# MCU_FSS0_HYPERBUS1P0_0_HPB_ECC_AGGR register map
Vendor: Texas Instruments
Peripheral module from a debugger description file (folder J721S2).
Registers are 32-bit, access not given, reset 0x0 unless marked. A register's access mark holds for its fields unless they carry their own. Offsets are as the file gives them; lines under a group give offsets from that group; [hi:lo] are bit positions; {n}, {i} and the like mark numbered series; 'fields as' and 'values as' point back to an identical list; <NAME> marks a mode.

## MCU_FSS0_HYPERBUS1P0_0_HPB_ECC_AGGR
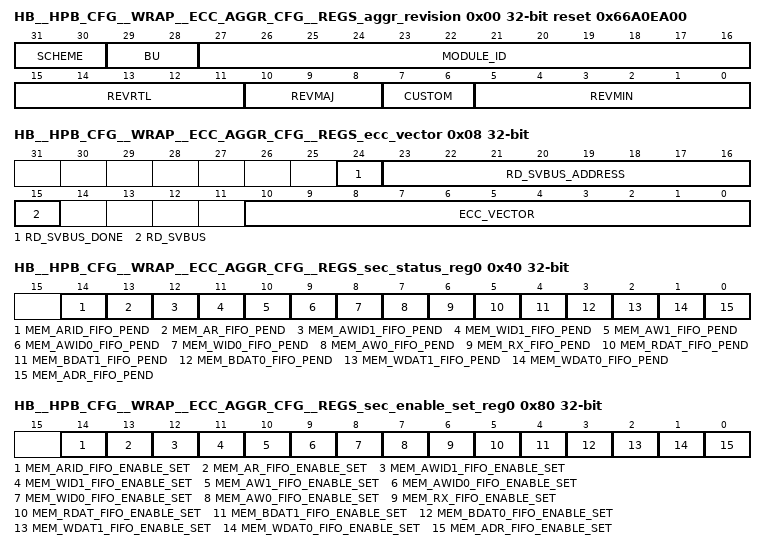
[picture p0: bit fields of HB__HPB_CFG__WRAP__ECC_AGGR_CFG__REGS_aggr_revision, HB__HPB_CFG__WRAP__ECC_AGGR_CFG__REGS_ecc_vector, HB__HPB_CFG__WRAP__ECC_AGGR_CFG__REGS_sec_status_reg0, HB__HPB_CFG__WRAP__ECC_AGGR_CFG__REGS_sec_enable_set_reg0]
0x00 HB__HPB_CFG__WRAP__ECC_AGGR_CFG__REGS_aggr_revision ro reset 0x66A0EA00 — Revision parameters
  [31:30] SCHEME
  [29:28] BU
  [27:16] MODULE_ID
  [15:11] REVRTL — RTL version
  [10:8] REVMAJ — Major version
  [7:6] CUSTOM — Custom version
  [5:0] REVMIN — Minor version
0x08 HB__HPB_CFG__WRAP__ECC_AGGR_CFG__REGS_ecc_vector — ECC Vector Register
  [24] RD_SVBUS_DONE — Status to indicate if read on serial VBUS is complete, write of any value will clear this bit. (access R/W1TC)
  [23:16] RD_SVBUS_ADDRESS rw — Read address
  [15] RD_SVBUS — Write 1 to trigger a read on the serial VBUS (access R/W1TS)
  [10:0] ECC_VECTOR rw — Value written to select the corresponding ECC RAM for control or status
0x0C HB__HPB_CFG__WRAP__ECC_AGGR_CFG__REGS_misc_status ro reset 0xF — Misc Status
  [10:0] NUM_RAMS — Indicates the number of RAMS serviced by the ECC aggregator
0x10 HB__HPB_CFG__WRAP__ECC_AGGR_CFG__REGS_reserved_svbus rw — Reference other documents that contain the ECC RAM wrapper and EDC controller serial vbus register sets.
  [31:0] DATA — Serial VBUS register data
0x3C HB__HPB_CFG__WRAP__ECC_AGGR_CFG__REGS_sec_eoi_reg — EOI Register
  [0] EOI_WR — EOI Register (access R/W1TS)
0x40 HB__HPB_CFG__WRAP__ECC_AGGR_CFG__REGS_sec_status_reg0 — Interrupt Status Register 0
  [14] MEM_ARID_FIFO_PEND — Interrupt Pending Status for mem_arid_fifo_pend (access R/W1TS)
  [13] MEM_AR_FIFO_PEND — Interrupt Pending Status for mem_ar_fifo_pend (access R/W1TS)
  [12] MEM_AWID1_FIFO_PEND — Interrupt Pending Status for mem_awid1_fifo_pend (access R/W1TS)
  [11] MEM_WID1_FIFO_PEND — Interrupt Pending Status for mem_wid1_fifo_pend (access R/W1TS)
  [10] MEM_AW1_FIFO_PEND — Interrupt Pending Status for mem_aw1_fifo_pend (access R/W1TS)
  [9] MEM_AWID0_FIFO_PEND — Interrupt Pending Status for mem_awid0_fifo_pend (access R/W1TS)
  [8] MEM_WID0_FIFO_PEND — Interrupt Pending Status for mem_wid0_fifo_pend (access R/W1TS)
  [7] MEM_AW0_FIFO_PEND — Interrupt Pending Status for mem_aw0_fifo_pend (access R/W1TS)
  [6] MEM_RX_FIFO_PEND — Interrupt Pending Status for mem_rx_fifo_pend (access R/W1TS)
  [5] MEM_RDAT_FIFO_PEND — Interrupt Pending Status for mem_rdat_fifo_pend (access R/W1TS)
  [4] MEM_BDAT1_FIFO_PEND — Interrupt Pending Status for mem_bdat1_fifo_pend (access R/W1TS)
  [3] MEM_BDAT0_FIFO_PEND — Interrupt Pending Status for mem_bdat0_fifo_pend (access R/W1TS)
  [2] MEM_WDAT1_FIFO_PEND — Interrupt Pending Status for mem_wdat1_fifo_pend (access R/W1TS)
  [1] MEM_WDAT0_FIFO_PEND — Interrupt Pending Status for mem_wdat0_fifo_pend (access R/W1TS)
  [0] MEM_ADR_FIFO_PEND — Interrupt Pending Status for mem_adr_fifo_pend (access R/W1TS)
0x80 HB__HPB_CFG__WRAP__ECC_AGGR_CFG__REGS_sec_enable_set_reg0 — Interrupt Enable Set Register 0
  [14] MEM_ARID_FIFO_ENABLE_SET — Interrupt Enable Set Register for mem_arid_fifo_pend (access R/W1TS)
  [13] MEM_AR_FIFO_ENABLE_SET — Interrupt Enable Set Register for mem_ar_fifo_pend (access R/W1TS)
  [12] MEM_AWID1_FIFO_ENABLE_SET — Interrupt Enable Set Register for mem_awid1_fifo_pend (access R/W1TS)
  [11] MEM_WID1_FIFO_ENABLE_SET — Interrupt Enable Set Register for mem_wid1_fifo_pend (access R/W1TS)
  [10] MEM_AW1_FIFO_ENABLE_SET — Interrupt Enable Set Register for mem_aw1_fifo_pend (access R/W1TS)
  [9] MEM_AWID0_FIFO_ENABLE_SET — Interrupt Enable Set Register for mem_awid0_fifo_pend (access R/W1TS)
  [8] MEM_WID0_FIFO_ENABLE_SET — Interrupt Enable Set Register for mem_wid0_fifo_pend (access R/W1TS)
  [7] MEM_AW0_FIFO_ENABLE_SET — Interrupt Enable Set Register for mem_aw0_fifo_pend (access R/W1TS)
  [6] MEM_RX_FIFO_ENABLE_SET — Interrupt Enable Set Register for mem_rx_fifo_pend (access R/W1TS)
  [5] MEM_RDAT_FIFO_ENABLE_SET — Interrupt Enable Set Register for mem_rdat_fifo_pend (access R/W1TS)
  [4] MEM_BDAT1_FIFO_ENABLE_SET — Interrupt Enable Set Register for mem_bdat1_fifo_pend (access R/W1TS)
  [3] MEM_BDAT0_FIFO_ENABLE_SET — Interrupt Enable Set Register for mem_bdat0_fifo_pend (access R/W1TS)
  [2] MEM_WDAT1_FIFO_ENABLE_SET — Interrupt Enable Set Register for mem_wdat1_fifo_pend (access R/W1TS)
  [1] MEM_WDAT0_FIFO_ENABLE_SET — Interrupt Enable Set Register for mem_wdat0_fifo_pend (access R/W1TS)
  [0] MEM_ADR_FIFO_ENABLE_SET — Interrupt Enable Set Register for mem_adr_fifo_pend (access R/W1TS)
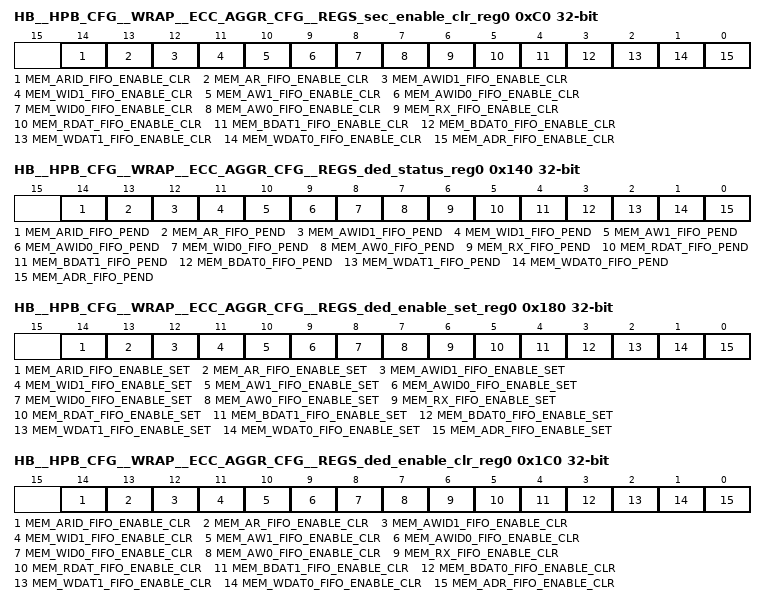
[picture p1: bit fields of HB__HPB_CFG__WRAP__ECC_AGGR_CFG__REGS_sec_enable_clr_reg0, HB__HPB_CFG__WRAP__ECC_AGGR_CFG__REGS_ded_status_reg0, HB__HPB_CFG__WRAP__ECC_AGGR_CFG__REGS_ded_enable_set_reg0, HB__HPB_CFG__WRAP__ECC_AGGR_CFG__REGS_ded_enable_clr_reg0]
0xC0 HB__HPB_CFG__WRAP__ECC_AGGR_CFG__REGS_sec_enable_clr_reg0 — Interrupt Enable Clear Register 0
  [14] MEM_ARID_FIFO_ENABLE_CLR — Interrupt Enable Clear Register for mem_arid_fifo_pend (access R/W1TC)
  [13] MEM_AR_FIFO_ENABLE_CLR — Interrupt Enable Clear Register for mem_ar_fifo_pend (access R/W1TC)
  [12] MEM_AWID1_FIFO_ENABLE_CLR — Interrupt Enable Clear Register for mem_awid1_fifo_pend (access R/W1TC)
  [11] MEM_WID1_FIFO_ENABLE_CLR — Interrupt Enable Clear Register for mem_wid1_fifo_pend (access R/W1TC)
  [10] MEM_AW1_FIFO_ENABLE_CLR — Interrupt Enable Clear Register for mem_aw1_fifo_pend (access R/W1TC)
  [9] MEM_AWID0_FIFO_ENABLE_CLR — Interrupt Enable Clear Register for mem_awid0_fifo_pend (access R/W1TC)
  [8] MEM_WID0_FIFO_ENABLE_CLR — Interrupt Enable Clear Register for mem_wid0_fifo_pend (access R/W1TC)
  [7] MEM_AW0_FIFO_ENABLE_CLR — Interrupt Enable Clear Register for mem_aw0_fifo_pend (access R/W1TC)
  [6] MEM_RX_FIFO_ENABLE_CLR — Interrupt Enable Clear Register for mem_rx_fifo_pend (access R/W1TC)
  [5] MEM_RDAT_FIFO_ENABLE_CLR — Interrupt Enable Clear Register for mem_rdat_fifo_pend (access R/W1TC)
  [4] MEM_BDAT1_FIFO_ENABLE_CLR — Interrupt Enable Clear Register for mem_bdat1_fifo_pend (access R/W1TC)
  [3] MEM_BDAT0_FIFO_ENABLE_CLR — Interrupt Enable Clear Register for mem_bdat0_fifo_pend (access R/W1TC)
  [2] MEM_WDAT1_FIFO_ENABLE_CLR — Interrupt Enable Clear Register for mem_wdat1_fifo_pend (access R/W1TC)
  [1] MEM_WDAT0_FIFO_ENABLE_CLR — Interrupt Enable Clear Register for mem_wdat0_fifo_pend (access R/W1TC)
  [0] MEM_ADR_FIFO_ENABLE_CLR — Interrupt Enable Clear Register for mem_adr_fifo_pend (access R/W1TC)
0x13C HB__HPB_CFG__WRAP__ECC_AGGR_CFG__REGS_ded_eoi_reg — EOI Register
  [0] EOI_WR — EOI Register (access R/W1TS)
0x140 HB__HPB_CFG__WRAP__ECC_AGGR_CFG__REGS_ded_status_reg0 — Interrupt Status Register 0
  fields as HB__HPB_CFG__WRAP__ECC_AGGR_CFG__REGS_sec_status_reg0
0x180 HB__HPB_CFG__WRAP__ECC_AGGR_CFG__REGS_ded_enable_set_reg0 — Interrupt Enable Set Register 0
  fields as HB__HPB_CFG__WRAP__ECC_AGGR_CFG__REGS_sec_enable_set_reg0
0x1C0 HB__HPB_CFG__WRAP__ECC_AGGR_CFG__REGS_ded_enable_clr_reg0 — Interrupt Enable Clear Register 0
  fields as HB__HPB_CFG__WRAP__ECC_AGGR_CFG__REGS_sec_enable_clr_reg0
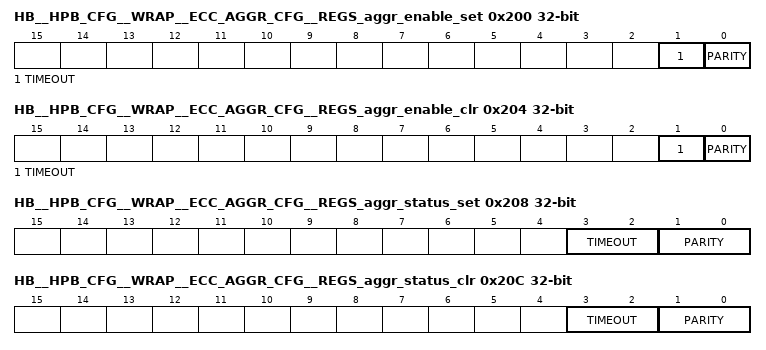
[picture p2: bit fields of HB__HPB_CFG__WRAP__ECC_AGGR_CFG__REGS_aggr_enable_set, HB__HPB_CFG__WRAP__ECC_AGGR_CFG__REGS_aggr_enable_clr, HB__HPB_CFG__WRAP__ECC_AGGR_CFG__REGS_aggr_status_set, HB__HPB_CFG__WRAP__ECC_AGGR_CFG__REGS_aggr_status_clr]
0x200 HB__HPB_CFG__WRAP__ECC_AGGR_CFG__REGS_aggr_enable_set — AGGR interrupt enable set Register
  [1] TIMEOUT — interrupt enable set for svbus timeout errors (access R/W1TS)
  [0] PARITY — interrupt enable set for parity errors (access R/W1TS)
0x204 HB__HPB_CFG__WRAP__ECC_AGGR_CFG__REGS_aggr_enable_clr — AGGR interrupt enable clear Register
  [1] TIMEOUT — interrupt enable clear for svbus timeout errors (access R/W1TC)
  [0] PARITY — interrupt enable clear for parity errors (access R/W1TC)
0x208 HB__HPB_CFG__WRAP__ECC_AGGR_CFG__REGS_aggr_status_set — AGGR interrupt status set Register
  [3:2] TIMEOUT — interrupt status set for svbus timeout errors (access R/WI)
  [1:0] PARITY — interrupt status set for parity errors (access R/WI)
0x20C HB__HPB_CFG__WRAP__ECC_AGGR_CFG__REGS_aggr_status_clr — AGGR interrupt status clear Register
  [3:2] TIMEOUT — interrupt status clear for svbus timeout errors (access R/WD)
  [1:0] PARITY — interrupt status clear for parity errors (access R/WD)
